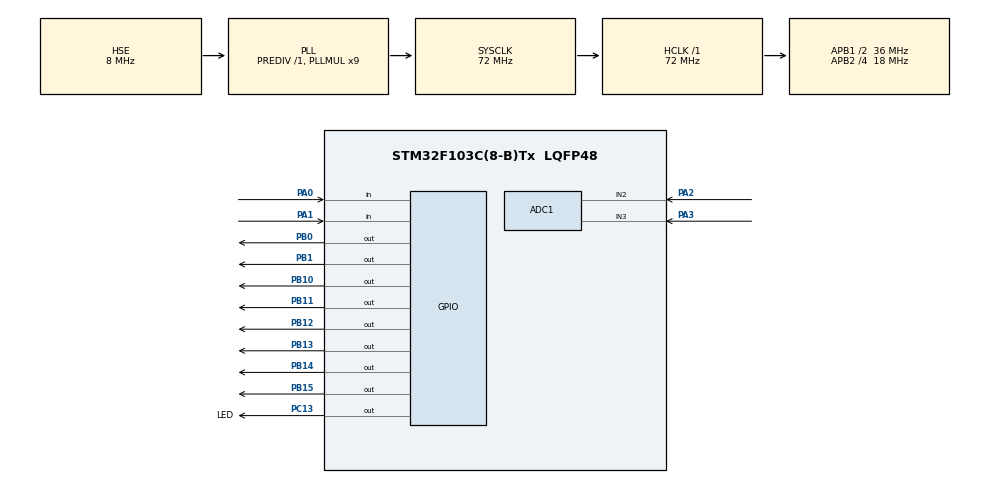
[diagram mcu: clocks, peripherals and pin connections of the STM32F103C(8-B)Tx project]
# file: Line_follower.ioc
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ADC1.Channel-1\#ChannelRegularConversion=ADC_CHANNEL_2
ADC1.NbrOfConversionFlag=1
ADC1.Rank-1\#ChannelRegularConversion=1
ADC1.SamplingTime-1\#ChannelRegularConversion=ADC_SAMPLETIME_239CYCLES_5
ADC1.master=1
FREERTOS.INCLUDE_vTaskDelayUntil=1
FREERTOS.Tasks01=defaultTask,0,128,StartDefaultTask,Default,NULL,Dynamic,NULL,NULL
Mcu.Family=STM32F1
Mcu.Name=STM32F103C(8-B)Tx
Mcu.Package=LQFP48
NVIC.PriorityGroup=NVIC_PRIORITYGROUP_4
NVIC.TIM2_IRQn=true\:5\:0\:false\:false\:true\:true\:true\:true\:true
NVIC.TIM4_IRQn=true\:15\:0\:false\:false\:true\:false\:false\:true\:true
NVIC.TimeBase=TIM4_IRQn
NVIC.TimeBaseIP=TIM4
PA0-WKUP.GPIO_PuPd=GPIO_PULLUP
PA0-WKUP.Signal=GPIO_Input
PA1.GPIO_PuPd=GPIO_PULLUP
PA1.Signal=GPIO_Input
PA13.Mode=Serial_Wire
PA13.Signal=SYS_JTMS-SWDIO
PA14.Mode=Serial_Wire
PA14.Signal=SYS_JTCK-SWCLK
PA2.Signal=ADCx_IN2
PA3.Signal=ADCx_IN3
PB0.Signal=GPIO_Output
PB1.Signal=GPIO_Output
PB10.Signal=GPIO_Output
PB11.Signal=GPIO_Output
PB12.Signal=GPIO_Output
PB13.Signal=GPIO_Output
PB14.Signal=GPIO_Output
PB15.Signal=GPIO_Output
PC13.GPIO_Label=LED
PC13.GPIO_ModeDefaultOutputPP=GPIO_MODE_OUTPUT_PP
PC13.GPIO_PuPd=GPIO_NOPULL
PC13.PinState=GPIO_PIN_SET
PC13.Signal=GPIO_Output
PD0-OSC_IN.Mode=HSE-External-Oscillator
PD0-OSC_IN.Signal=RCC_OSC_IN
PD1-OSC_OUT.Mode=HSE-External-Oscillator
PD1-OSC_OUT.Signal=RCC_OSC_OUT
ProjectManager.HeapSize=0x200
ProjectManager.StackSize=0x400
ProjectManager.TargetToolchain=CMake
RCC.ADCPresc=RCC_ADCPCLK2_DIV6
RCC.AHBFreq_Value=72000000
RCC.APB1CLKDivider=RCC_HCLK_DIV2
RCC.APB1Freq_Value=36000000
RCC.APB1TimFreq_Value=72000000
RCC.APB2CLKDivider=RCC_HCLK_DIV4
RCC.APB2Freq_Value=18000000
RCC.APB2TimFreq_Value=36000000
RCC.HCLKFreq_Value=72000000
RCC.PLLMUL=RCC_PLL_MUL9
RCC.PLLSourceVirtual=RCC_PLLSOURCE_HSE
RCC.SYSCLKFreq_VALUE=72000000
RCC.SYSCLKSource=RCC_SYSCLKSOURCE_PLLCLK
RCC.USBFreq_Value=72000000
SH.ADCx_IN2.0=ADC1_IN2,IN2
SH.ADCx_IN3.0=ADC1_IN3,IN3
TIM2.Period=999
TIM2.Prescaler=71
VP_FREERTOS_VS_CMSIS_V1.Mode=CMSIS_V1
VP_SYS_VS_tim4.Mode=TIM4
VP_TIM2_VS_ClockSourceINT.Mode=Internal
board=custom

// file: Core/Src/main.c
/* USER CODE BEGIN Header */
/**
 ******************************************************************************
 * @file           : main.c
 * @brief          : Main program body
 ******************************************************************************
 * @attention
 *
 * Copyright (c) 2026 STMicroelectronics.
 * All rights reserved.
 *
 * This software is licensed under terms that can be found in the LICENSE file
 * in the root directory of this software component.
 * If no LICENSE file comes with this software, it is provided AS-IS.
 *
 ******************************************************************************
 */
/* USER CODE END Header */
#include "main.h"
#include "cmsis_os.h"
#include "adc.h"
#include "tim.h"
#include "gpio.h"

/* USER CODE BEGIN Includes */
#include "Car.h"
#include "motor.h"
/* USER CODE END Includes */

void SystemClock_Config(void);
void MX_FREERTOS_Init(void);

int main(void)
{

  /* USER CODE BEGIN 1 */
  *(int *)0xE000ED14 = *(int *)0xE000ED14 & ~0x18;
  /* USER CODE END 1 */

  /* MCU Configuration--------------------------------------------------------*/

  /* Reset of all peripherals, Initializes the Flash interface and the Systick. */
  HAL_Init();

  /* Configure the system clock */
  SystemClock_Config();

  /* Initialize all configured peripherals */
  MX_GPIO_Init();
  MX_TIM2_Init();
  MX_ADC1_Init();
  /* USER CODE BEGIN 2 */
  CarInit();
  /* USER CODE END 2 */

  /* Create CubeMX FreeRTOS objects. */
  MX_FREERTOS_Init();

  /* Start scheduler */
  osKernelStart();

  /* We should never get here as control is now taken by the scheduler */

  /* Infinite loop */
  while (1) {

  }
}

void SystemClock_Config(void)
{
  RCC_OscInitTypeDef RCC_OscInitStruct = {0};
  RCC_ClkInitTypeDef RCC_ClkInitStruct = {0};
  RCC_PeriphCLKInitTypeDef PeriphClkInit = {0};

  /** Initializes the RCC Oscillators according to the specified parameters
  * in the RCC_OscInitTypeDef structure.
  */
  RCC_OscInitStruct.OscillatorType = RCC_OSCILLATORTYPE_HSE;
  RCC_OscInitStruct.HSEState = RCC_HSE_ON;
  RCC_OscInitStruct.HSEPredivValue = RCC_HSE_PREDIV_DIV1;
  RCC_OscInitStruct.HSIState = RCC_HSI_ON;
  RCC_OscInitStruct.PLL.PLLState = RCC_PLL_ON;
  RCC_OscInitStruct.PLL.PLLSource = RCC_PLLSOURCE_HSE;
  RCC_OscInitStruct.PLL.PLLMUL = RCC_PLL_MUL9;
  if (HAL_RCC_OscConfig(&RCC_OscInitStruct) != HAL_OK)
  {
    Error_Handler();
  }

  /** Initializes the CPU, AHB and APB buses clocks
  */
  RCC_ClkInitStruct.ClockType = RCC_CLOCKTYPE_HCLK|RCC_CLOCKTYPE_SYSCLK
                              |RCC_CLOCKTYPE_PCLK1|RCC_CLOCKTYPE_PCLK2;
  RCC_ClkInitStruct.SYSCLKSource = RCC_SYSCLKSOURCE_PLLCLK;
  RCC_ClkInitStruct.AHBCLKDivider = RCC_SYSCLK_DIV1;
  RCC_ClkInitStruct.APB1CLKDivider = RCC_HCLK_DIV2;
  RCC_ClkInitStruct.APB2CLKDivider = RCC_HCLK_DIV4;

  if (HAL_RCC_ClockConfig(&RCC_ClkInitStruct, FLASH_LATENCY_2) != HAL_OK)
  {
    Error_Handler();
  }
  PeriphClkInit.PeriphClockSelection = RCC_PERIPHCLK_ADC;
  PeriphClkInit.AdcClockSelection = RCC_ADCPCLK2_DIV6;
  if (HAL_RCCEx_PeriphCLKConfig(&PeriphClkInit) != HAL_OK)
  {
    Error_Handler();
  }
}

void HAL_TIM_PeriodElapsedCallback(TIM_HandleTypeDef *htim)
{
  if (htim->Instance == TIM4)
  {
    HAL_IncTick();
  }
  /* USER CODE BEGIN Callback 1 */
  if (htim->Instance == TIM2)
    MotorControl();
  /* USER CODE END Callback 1 */
}

void Error_Handler(void)
{
  __disable_irq();
  while (1) {
  }
}
#ifdef USE_FULL_ASSERT
/**
  * @brief  Reports the name of the source file and the source line number
  *         where the assert_param error has occurred.
  * @param  file: pointer to the source file name
  * @param  line: assert_param error line source number
  * @retval None
  */
void assert_failed(uint8_t *file, uint32_t line)
{
  /* USER CODE BEGIN 6 */
  /* User can add his own implementation to report the file name and line
     number, ex: printf("Wrong parameters value: file %s on line %d\r\n", file,
     line) */
  /* USER CODE END 6 */
}
#endif /* USE_FULL_ASSERT */

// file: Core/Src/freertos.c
/* USER CODE BEGIN Header */
/**
 ******************************************************************************
 * File Name          : freertos.c
 * Description        : Code for freertos applications
 ******************************************************************************
 * @attention
 *
 * Copyright (c) 2026 STMicroelectronics.
 * All rights reserved.
 *
 * This software is licensed under terms that can be found in the LICENSE file
 * in the root directory of this software component.
 * If no LICENSE file comes with this software, it is provided AS-IS.
 *
 ******************************************************************************
 */
/* USER CODE END Header */

#include "FreeRTOS.h"
#include "task.h"
#include "main.h"
#include "cmsis_os.h"

osThreadId defaultTaskHandle;

void StartDefaultTask(void const * argument);

void MX_FREERTOS_Init(void); /* (MISRA C 2004 rule 8.1) */

/* GetIdleTaskMemory prototype (linked to static allocation support) */
void vApplicationGetIdleTaskMemory( StaticTask_t **ppxIdleTaskTCBBuffer, StackType_t **ppxIdleTaskStackBuffer, uint32_t *pulIdleTaskStackSize );

/* USER CODE BEGIN GET_IDLE_TASK_MEMORY */
static StaticTask_t xIdleTaskTCBBuffer;
static StackType_t xIdleStack[configMINIMAL_STACK_SIZE];

void vApplicationGetIdleTaskMemory( StaticTask_t **ppxIdleTaskTCBBuffer, StackType_t **ppxIdleTaskStackBuffer, uint32_t *pulIdleTaskStackSize )
{
  *ppxIdleTaskTCBBuffer = &xIdleTaskTCBBuffer;
  *ppxIdleTaskStackBuffer = &xIdleStack[0];
  *pulIdleTaskStackSize = configMINIMAL_STACK_SIZE;
  /* place for user code */
}
/* USER CODE END GET_IDLE_TASK_MEMORY */

void MX_FREERTOS_Init(void) {

  /* Create the thread(s) */
  /* definition and creation of defaultTask */
  osThreadDef(defaultTask, StartDefaultTask, osPriorityNormal, 0, 128);
  defaultTaskHandle = osThreadCreate(osThread(defaultTask), NULL);

}

void StartDefaultTask(void const * argument)
{
  for (;;) {
    osDelay(1);
  }
}
